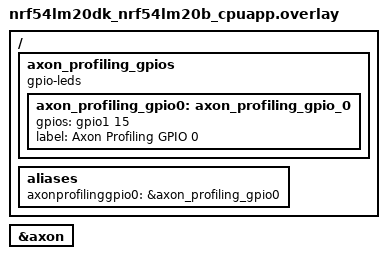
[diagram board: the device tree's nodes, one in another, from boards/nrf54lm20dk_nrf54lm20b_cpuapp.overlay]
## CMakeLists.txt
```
# SPDX-License-Identifier: Apache-2.0

cmake_minimum_required(VERSION 3.20.0)

set(CMAKE_COMPILE_WARNING_AS_ERROR ON)

find_package(Zephyr REQUIRED HINTS $ENV{ZEPHYR_BASE})
project(axon_intrinsics VERSION 0.1.0 LANGUAGES C)

target_sources(app PRIVATE
    src/nrf_axon_app_test_dsp_intrinsics_zephyr.c
    src/nrf_axon_app_test_dsp_intrinsics.c
)
```

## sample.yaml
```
sample:
  description: DSP intrinsics test to run and validate Axon NPU intrinsic functions
  name: nRF Edge AI Axon DSP Intrinsics test
tests:
  axon.intrinsics:
    harness: console
    harness_config:
      type: multi_line
      ordered: true
      regex:
        - "TEST:\\tAXON_INTRINSICS\\tCASE COUNT\\t(\\d+)"
        - "TEST:\\tAXON_INTRINSICS\\tCOMPLETE\\tPASS COUNT\\t(\\d+)\\tFAIL COUNT\\t(0)"
    sysbuild: true
    platform_allow:
      - nrf54lm20dk/nrf54lm20b/cpuapp
      - nrf7120dk/nrf7120e/cpuapp
      - nrf9251dk/nrf9251/cpuapp
    integration_platforms:
      - nrf54lm20dk/nrf54lm20b/cpuapp
```

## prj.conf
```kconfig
#
# Copyright (c) 2026 Nordic Semiconductor ASA
#
# SPDX-License-Identifier: LicenseRef-Nordic-5-Clause
#

CONFIG_PRINTK=y
CONFIG_LOG=y
CONFIG_LOG_MODE_IMMEDIATE=y

CONFIG_NRF_AXON=y

CONFIG_OUTPUT_DISASSEMBLY=y
CONFIG_OUTPUT_DISASSEMBLE_ALL=y

CONFIG_MAIN_STACK_SIZE=4096

CONFIG_DEBUG_OPTIMIZATIONS=n
```

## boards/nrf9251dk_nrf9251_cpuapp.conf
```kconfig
#
# Copyright (c) 2026 Nordic Semiconductor ASA
#
# SPDX-License-Identifier: LicenseRef-Nordic-5-Clause
#

CONFIG_NRFS=y
CONFIG_NRFS_MRAM_SERVICE_ENABLED=y
CONFIG_ONOFF=y
CONFIG_DCACHE=n
```

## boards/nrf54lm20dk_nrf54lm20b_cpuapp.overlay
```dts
/*
 * Copyright (c) 2023 Nordic Semiconductor ASA
 *
 * SPDX-License-Identifier: Apache-2.0
 */

/ {
	// specify axon profiling gpio
	axon_profiling_gpios {
		compatible = "gpio-leds";

		axon_profiling_gpio0: axon_profiling_gpio_0 {
			gpios = <&gpio1 15 GPIO_ACTIVE_HIGH>;
			label = "Axon Profiling GPIO 0";
		};
	};

	aliases {
		axonprofilinggpio0 = &axon_profiling_gpio0;
	};
};

// Include Axons
&axon {
	status = "okay";
};
```

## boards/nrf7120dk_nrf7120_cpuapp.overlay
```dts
/*
 * Copyright (c) 2023 Nordic Semiconductor ASA
 *
 * SPDX-License-Identifier: Apache-2.0
 */

// Include Axons
&global_peripherals {
	axon: axon@56000 {
		compatible = "nordic,axon";
		reg = <0x56000 0x1000>;
		interrupts = <86 NRF_DEFAULT_IRQ_PRIORITY>;
		status = "okay";
	};
};
```

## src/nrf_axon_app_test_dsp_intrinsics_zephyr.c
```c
/*
 * Copyright (c) 2022 Nordic Semiconductor ASA
 *
 * SPDX-License-Identifier: LicenseRef-Nordic-5-Clause
 */

#include <zephyr/kernel.h>
#include <zephyr/irq.h>
#include <zephyr/sys_clock.h>
#include <zephyr/sys/printk.h>

#include <zephyr/logging/log.h>

// #define MY_LOG_LEVEL LOG_LEVEL_NONE
#define MY_LOG_LEVEL LOG_LEVEL_DBG

LOG_MODULE_REGISTER(axon_test_app, MY_LOG_LEVEL);

extern void main_intrinsics_test(void);
int main(void)
{
    printk("nrf_axon_app_test_dsp_intrinsics on %s\n", CONFIG_BOARD);

    // Start inference
    main_intrinsics_test();

    k_sleep(K_FOREVER);
  return 0;
}
```
